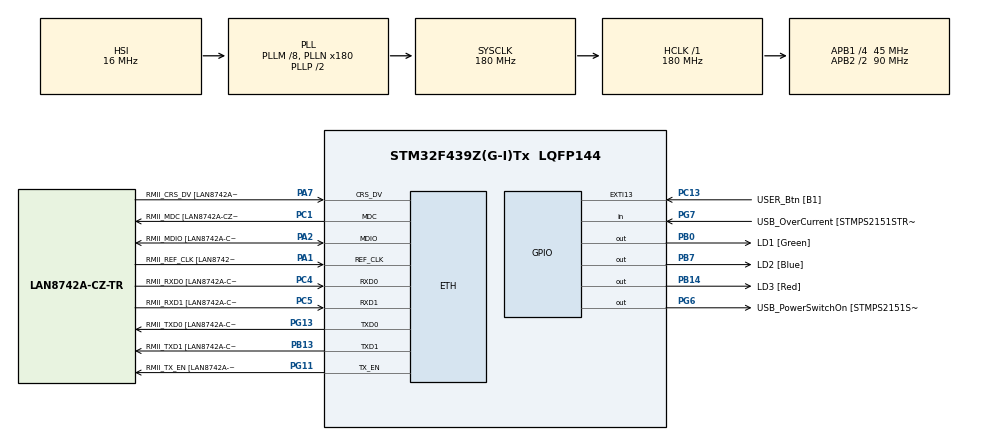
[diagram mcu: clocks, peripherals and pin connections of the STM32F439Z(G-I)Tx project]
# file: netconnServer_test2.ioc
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ETH.MediaInterface=ETH_MEDIA_INTERFACE_RMII
ETH.PhyAddress=0
ETH.RxMode=ETH_RXINTERRUPT_MODE
FREERTOS.Tasks01=defaultTask,24,128,StartDefaultTask,Default,NULL,Dynamic,NULL,NULL;blinkingLEDTask,24,128,startBlinkingLED,Default,NULL,Dynamic,NULL,NULL
FREERTOS.configUSE_NEWLIB_REENTRANT=1
HASH.KeySize=17
HASH.SecureHashAlgorithmType=HMAC SHA256
HASH.pKey=00 01 02 03 04 05 06 07 08 09 0A 0B 0C 0D 0E 0F 10
HASH.pKeyInput=000102030405060708090A0B0C0D0E0F10
LWIP.GATEWAY_ADDRESS=169.254.084.058
LWIP.IP_ADDRESS=169.254.084.057
LWIP.LWIP_DHCP=0
LWIP.LWIP_TCP_SACK_OUT=1
LWIP.MEMP_NUM_TCP_SEG=100
LWIP.MEM_SIZE=21*1024
LWIP.NETMASK_ADDRESS=255.255.000.000
LWIP.PBUF_POOL_BUFSIZE=1500
LWIP.TCP_MSS=1426
LWIP.TCP_SND_BUF=11408
LWIP.TCP_SND_QUEUELEN=100
LWIP.TCP_WND=11408
LWIP.Version=v2.1.2_Cube
Mcu.Family=STM32F4
Mcu.Name=STM32F439Z(G-I)Tx
Mcu.Package=LQFP144
NVIC.ETH_IRQn=true\:5\:0\:false\:false\:true\:true\:false\:true
NVIC.PriorityGroup=NVIC_PRIORITYGROUP_4
NVIC.TIM1_UP_TIM10_IRQn=true\:15\:0\:false\:false\:true\:false\:false\:true
NVIC.TimeBase=TIM1_UP_TIM10_IRQn
NVIC.TimeBaseIP=TIM1
PA1.GPIO_Label=RMII_REF_CLK [LAN8742A-CZ-TR_REFCLK0]
PA1.Mode=RMII
PA1.Signal=ETH_REF_CLK
PA10.GPIO_Label=USB_ID
PA10.Signal=USB_OTG_FS_ID
PA11.GPIO_Label=USB_DM
PA11.Signal=USB_OTG_FS_DM
PA12.GPIO_Label=USB_DP
PA12.Signal=USB_OTG_FS_DP
PA13.GPIO_Label=TMS
PA13.Signal=SYS_JTMS-SWDIO
PA14.GPIO_Label=TCK
PA14.Signal=SYS_JTCK-SWCLK
PA2.GPIO_Label=RMII_MDIO [LAN8742A-CZ-TR_MDIO]
PA2.Mode=RMII
PA2.Signal=ETH_MDIO
PA7.GPIO_Label=RMII_CRS_DV [LAN8742A-CZ-TR_CRS_DV]
PA7.Mode=RMII
PA7.Signal=ETH_CRS_DV
PA8.GPIO_Label=USB_SOF [TP1]
PA8.Signal=USB_OTG_FS_SOF
PA9.GPIO_Label=USB_VBUS
PA9.Signal=USB_OTG_FS_VBUS
PB0.GPIO_Label=LD1 [Green]
PB0.Signal=GPIO_Output
PB13.GPIO_Label=RMII_TXD1 [LAN8742A-CZ-TR_TXD1]
PB13.Mode=RMII
PB13.Signal=ETH_TXD1
PB14.GPIO_Label=LD3 [Red]
PB14.Signal=GPIO_Output
PB7.GPIO_Label=LD2 [Blue]
PB7.Signal=GPIO_Output
PC1.GPIO_Label=RMII_MDC [LAN8742A-CZ-TR_MDC]
PC1.Mode=RMII
PC1.Signal=ETH_MDC
PC13.GPIO_Label=USER_Btn [B1]
PC13.Signal=GPXTI13
PC14/OSC32_IN.Signal=RCC_OSC32_IN
PC15/OSC32_OUT.Signal=RCC_OSC32_OUT
PC4.GPIO_Label=RMII_RXD0 [LAN8742A-CZ-TR_RXD0]
PC4.Mode=RMII
PC4.Signal=ETH_RXD0
PC5.GPIO_Label=RMII_RXD1 [LAN8742A-CZ-TR_RXD1]
PC5.Mode=RMII
PC5.Signal=ETH_RXD1
PD8.GPIO_Label=STLK_RX [STM32F103CBT6_PA3]
PD8.Signal=USART3_TX
PD9.GPIO_Label=STLK_TX [STM32F103CBT6_PA2]
PD9.Signal=USART3_RX
PG11.GPIO_Label=RMII_TX_EN [LAN8742A-CZ-TR_TXEN]
PG11.Mode=RMII
PG11.Signal=ETH_TX_EN
PG13.GPIO_Label=RMII_TXD0 [LAN8742A-CZ-TR_TXD0]
PG13.Mode=RMII
PG13.Signal=ETH_TXD0
PG6.GPIO_Label=USB_PowerSwitchOn [STMPS2151STR_EN]
PG6.Signal=GPIO_Output
PG7.GPIO_Label=USB_OverCurrent [STMPS2151STR_FAULT]
PG7.Signal=GPIO_Input
PH0/OSC_IN.GPIO_Label=MCO [STM32F103CBT6_PA8]
PH0/OSC_IN.Mode=HSE-External-Oscillator
PH0/OSC_IN.Signal=RCC_OSC_IN
PH1/OSC_OUT.Mode=HSE-External-Oscillator
PH1/OSC_OUT.Signal=RCC_OSC_OUT
ProjectManager.HeapSize=0x200
ProjectManager.StackSize=0x400
ProjectManager.TargetToolchain=STM32CubeIDE
RCC.48MHZClocksFreq_Value=45000000
RCC.AHBFreq_Value=180000000
RCC.APB1CLKDivider=RCC_HCLK_DIV4
RCC.APB1Freq_Value=45000000
RCC.APB1TimFreq_Value=90000000
RCC.APB2CLKDivider=RCC_HCLK_DIV2
RCC.APB2Freq_Value=90000000
RCC.APB2TimFreq_Value=180000000
RCC.CortexFreq_Value=180000000
RCC.HCLKFreq_Value=180000000
RCC.HSE_VALUE=8000000
RCC.HSI_VALUE=16000000
RCC.LSE_VALUE=32768
RCC.PLLM=8
RCC.PLLMUL=RCC_PLL_MUL9
RCC.PLLN=180
RCC.PLLQ=8
RCC.PRESCALERUSB=RCC_USBCLKSOURCE_PLL_DIV1_5
RCC.SYSCLKFreq_VALUE=180000000
RCC.SYSCLKSource=RCC_SYSCLKSOURCE_PLLCLK
RCC.SYSCLKSourceVirtual=RCC_SYSCLKSOURCE_PLLCLK
RCC.USBFreq_Value=48000000
RCC.VCOOutputFreq_Value=360000000
VP_CRC_VS_CRC.Mode=CRC_Activate
VP_FREERTOS_VS_CMSIS_V2.Mode=CMSIS_V2
VP_HASH_VS_HASH.Mode=HASH_Activate
VP_LWIP_VS_Enabled.Mode=Enabled
VP_RNG_VS_RNG.Mode=RNG_Activate
VP_RTC_VS_RTC_Activate.Mode=RTC_Enabled
VP_SYS_VS_tim1.Mode=TIM1
board=NUCLEO-F439ZI

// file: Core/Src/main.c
/* USER CODE BEGIN Header */
/**
  ******************************************************************************
  * @file           : main.c
  * @brief          : Main program body
  ******************************************************************************
  * @attention
  *
  * <h2><center>&copy; Copyright (c) 2023 STMicroelectronics.
  * All rights reserved.</center></h2>
  *
  * This software component is licensed by ST under BSD 3-Clause license,
  * the "License"; You may not use this file except in compliance with the
  * License. You may obtain a copy of the License at:
  *                        opensource.org/licenses/BSD-3-Clause
  *
  ******************************************************************************
  */
/* USER CODE END Header */
#include "main.h"
#include "cmsis_os.h"
#include "crc.h"
#include "hash.h"
#include "lwip.h"
#include "rng.h"
#include "rtc.h"
#include "gpio.h"

/* USER CODE BEGIN Includes */
#include "tcp_server.h"
#include "uds_server.h"

/* USER CODE END Includes */

void SystemClock_Config(void);
void MX_FREERTOS_Init(void);

int main(void)
{

  /* MCU Configuration--------------------------------------------------------*/

  /* Reset of all peripherals, Initializes the Flash interface and the Systick. */
  HAL_Init();

  /* Configure the system clock */
  SystemClock_Config();

  /* Initialize all configured peripherals */
  MX_GPIO_Init();
  MX_HASH_Init();
  MX_RNG_Init();
  MX_CRC_Init();
  MX_RTC_Init();

  /* Init scheduler */
  osKernelInitialize();  /* Call init function for freertos objects (in freertos.c) */
  MX_FREERTOS_Init();

  /* Start scheduler */
  osKernelStart();

  /* We should never get here as control is now taken by the scheduler */
  /* Infinite loop */
  while (1)
  {

  }
}

void SystemClock_Config(void)
{
  RCC_OscInitTypeDef RCC_OscInitStruct = {0};
  RCC_ClkInitTypeDef RCC_ClkInitStruct = {0};

  /** Configure the main internal regulator output voltage
  */
  __HAL_RCC_PWR_CLK_ENABLE();
  __HAL_PWR_VOLTAGESCALING_CONFIG(PWR_REGULATOR_VOLTAGE_SCALE1);
  /** Initializes the RCC Oscillators according to the specified parameters
  * in the RCC_OscInitTypeDef structure.
  */
  RCC_OscInitStruct.OscillatorType = RCC_OSCILLATORTYPE_HSI|RCC_OSCILLATORTYPE_LSI;
  RCC_OscInitStruct.HSIState = RCC_HSI_ON;
  RCC_OscInitStruct.HSICalibrationValue = RCC_HSICALIBRATION_DEFAULT;
  RCC_OscInitStruct.LSIState = RCC_LSI_ON;
  RCC_OscInitStruct.PLL.PLLState = RCC_PLL_ON;
  RCC_OscInitStruct.PLL.PLLSource = RCC_PLLSOURCE_HSI;
  RCC_OscInitStruct.PLL.PLLM = 8;
  RCC_OscInitStruct.PLL.PLLN = 180;
  RCC_OscInitStruct.PLL.PLLP = RCC_PLLP_DIV2;
  RCC_OscInitStruct.PLL.PLLQ = 8;
  if (HAL_RCC_OscConfig(&RCC_OscInitStruct) != HAL_OK)
  {
    Error_Handler();
  }
  /** Activate the Over-Drive mode
  */
  if (HAL_PWREx_EnableOverDrive() != HAL_OK)
  {
    Error_Handler();
  }
  /** Initializes the CPU, AHB and APB buses clocks
  */
  RCC_ClkInitStruct.ClockType = RCC_CLOCKTYPE_HCLK|RCC_CLOCKTYPE_SYSCLK
                              |RCC_CLOCKTYPE_PCLK1|RCC_CLOCKTYPE_PCLK2;
  RCC_ClkInitStruct.SYSCLKSource = RCC_SYSCLKSOURCE_PLLCLK;
  RCC_ClkInitStruct.AHBCLKDivider = RCC_SYSCLK_DIV1;
  RCC_ClkInitStruct.APB1CLKDivider = RCC_HCLK_DIV4;
  RCC_ClkInitStruct.APB2CLKDivider = RCC_HCLK_DIV2;

  if (HAL_RCC_ClockConfig(&RCC_ClkInitStruct, FLASH_LATENCY_5) != HAL_OK)
  {
    Error_Handler();
  }
}

void HAL_TIM_PeriodElapsedCallback(TIM_HandleTypeDef *htim)
{
  if (htim->Instance == TIM1) {
    HAL_IncTick();
  }
}

void Error_Handler(void)
{
}

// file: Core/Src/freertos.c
/* USER CODE BEGIN Header */
/**
  ******************************************************************************
  * File Name          : freertos.c
  * Description        : Code for freertos applications
  ******************************************************************************
  * @attention
  *
  * Copyright (c) 2023 STMicroelectronics.
  * All rights reserved.
  *
  * This software is licensed under terms that can be found in the LICENSE file
  * in the root directory of this software component.
  * If no LICENSE file comes with this software, it is provided AS-IS.
  *
  ******************************************************************************
  */
/* USER CODE END Header */

#include "FreeRTOS.h"
#include "task.h"
#include "main.h"
#include "cmsis_os.h"

/* USER CODE BEGIN Includes */
#include "uds_server.h"
/* USER CODE END Includes */

/* Definitions for defaultTask */
osThreadId_t defaultTaskHandle;
const osThreadAttr_t defaultTask_attributes = {
  .name = "defaultTask",
  .stack_size = 128 * 4,
  .priority = (osPriority_t) osPriorityNormal,
};
/* Definitions for blinkingLEDTask */
osThreadId_t blinkingLEDTaskHandle;
const osThreadAttr_t blinkingLEDTask_attributes = {
  .name = "blinkingLEDTask",
  .stack_size = 128 * 4,
  .priority = (osPriority_t) osPriorityNormal,
};

void StartDefaultTask(void *argument);
void startBlinkingLED(void *argument);

extern void MX_LWIP_Init(void);
void MX_FREERTOS_Init(void); /* (MISRA C 2004 rule 8.1) */

void MX_FREERTOS_Init(void) {

  /* Create the thread(s) */
  /* creation of defaultTask */
  defaultTaskHandle = osThreadNew(StartDefaultTask, NULL, &defaultTask_attributes);

  /* creation of blinkingLEDTask */
  blinkingLEDTaskHandle = osThreadNew(startBlinkingLED, NULL, &blinkingLEDTask_attributes);

}

void StartDefaultTask(void *argument)
{
  /* init code for LWIP */
  MX_LWIP_Init();
  /* USER CODE BEGIN StartDefaultTask */
  UDS_init();
  /* Infinite loop */
  for(;;)
  {
    osDelay(1);
  }
  /* USER CODE END StartDefaultTask */
}

void startBlinkingLED(void *argument)
{
  /* USER CODE BEGIN startBlinkingLED */
  /* Infinite loop */
  for(;;)
  {
	  HAL_GPIO_TogglePin(LD1_GPIO_Port, LD1_Pin);
	  HAL_Delay(500);
	  osDelay(1);
  }
  /* USER CODE END startBlinkingLED */
}
